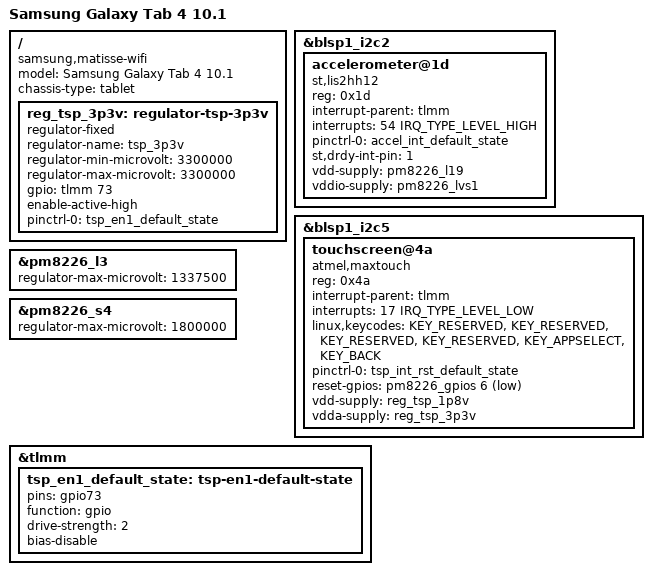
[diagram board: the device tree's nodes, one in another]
// SPDX-License-Identifier: BSD-3-Clause
/*
 * Copyright (c) 2022, Matti Lehtimäki <matti.lehtimaki@gmail.com>
 */

/dts-v1/;

#include "qcom-msm8226.dtsi"
#include "qcom-msm8226-samsung-matisse-common.dtsi"

/ {
	model = "Samsung Galaxy Tab 4 10.1";
	compatible = "samsung,matisse-wifi", "qcom,apq8026";
	chassis-type = "tablet";

	reg_tsp_3p3v: regulator-tsp-3p3v {
		compatible = "regulator-fixed";
		regulator-name = "tsp_3p3v";
		regulator-min-microvolt = <3300000>;
		regulator-max-microvolt = <3300000>;

		gpio = <&tlmm 73 GPIO_ACTIVE_HIGH>;
		enable-active-high;

		pinctrl-names = "default";
		pinctrl-0 = <&tsp_en1_default_state>;
	};
};

&blsp1_i2c2 {
	status = "okay";

	accelerometer@1d {
		compatible = "st,lis2hh12";
		reg = <0x1d>;

		interrupt-parent = <&tlmm>;
		interrupts = <54 IRQ_TYPE_LEVEL_HIGH>;

		pinctrl-names = "default";
		pinctrl-0 = <&accel_int_default_state>;

		st,drdy-int-pin = <1>;

		vdd-supply = <&pm8226_l19>;
		vddio-supply = <&pm8226_lvs1>;
	};
};

&blsp1_i2c5 {
	status = "okay";

	touchscreen@4a {
		compatible = "atmel,maxtouch";
		reg = <0x4a>;

		interrupt-parent = <&tlmm>;
		interrupts = <17 IRQ_TYPE_LEVEL_LOW>;

		linux,keycodes = <KEY_RESERVED>,
				 <KEY_RESERVED>,
				 <KEY_RESERVED>,
				 <KEY_RESERVED>,
				 <KEY_APPSELECT>,
				 <KEY_BACK>;

		pinctrl-names = "default";
		pinctrl-0 = <&tsp_int_rst_default_state>;

		reset-gpios = <&pm8226_gpios 6 GPIO_ACTIVE_LOW>;

		vdd-supply = <&reg_tsp_1p8v>;
		vdda-supply = <&reg_tsp_3p3v>;
	};
};

&pm8226_l3 {
	regulator-max-microvolt = <1337500>;
};

&pm8226_s4 {
	regulator-max-microvolt = <1800000>;
};

&tlmm {
	tsp_en1_default_state: tsp-en1-default-state {
		pins = "gpio73";
		function = "gpio";
		drive-strength = <2>;
		bias-disable;
	};
};
